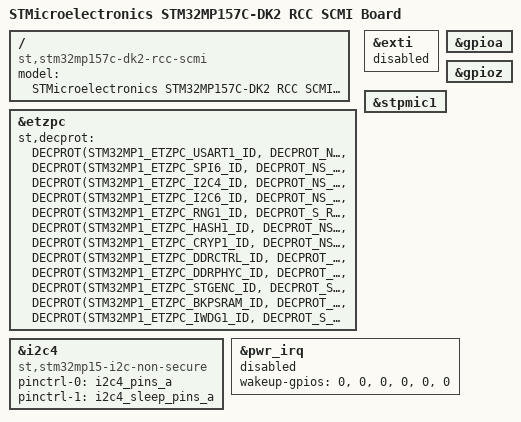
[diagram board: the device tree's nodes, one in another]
// SPDX-License-Identifier: (GPL-2.0+ OR BSD-3-Clause)
/*
 * Copyright (C) STMicroelectronics 2019-2026 - All Rights Reserved
 */

/dts-v1/;

#include "stm32mp157c-dk2.dts"

/ {
	model = "STMicroelectronics STM32MP157C-DK2 RCC SCMI Board";
	compatible = "st,stm32mp157c-dk2-rcc-scmi", "st,stm32mp157c-dk2", "st,stm32mp157";

	/delete-node/ scmi-regu;
};

&etzpc {
	st,decprot =
		<DECPROT(STM32MP1_ETZPC_USART1_ID, DECPROT_NS_RW, DECPROT_UNLOCK)>,
		<DECPROT(STM32MP1_ETZPC_SPI6_ID, DECPROT_NS_RW, DECPROT_UNLOCK)>,
		<DECPROT(STM32MP1_ETZPC_I2C4_ID, DECPROT_NS_RW, DECPROT_UNLOCK)>,
		<DECPROT(STM32MP1_ETZPC_I2C6_ID, DECPROT_NS_RW, DECPROT_UNLOCK)>,
		<DECPROT(STM32MP1_ETZPC_RNG1_ID, DECPROT_S_RW, DECPROT_UNLOCK)>,
		<DECPROT(STM32MP1_ETZPC_HASH1_ID, DECPROT_NS_RW, DECPROT_UNLOCK)>,
		<DECPROT(STM32MP1_ETZPC_CRYP1_ID, DECPROT_NS_RW, DECPROT_UNLOCK)>,
		<DECPROT(STM32MP1_ETZPC_DDRCTRL_ID, DECPROT_NS_R_S_W, DECPROT_LOCK)>,
		<DECPROT(STM32MP1_ETZPC_DDRPHYC_ID, DECPROT_NS_R_S_W, DECPROT_LOCK)>,
		<DECPROT(STM32MP1_ETZPC_STGENC_ID, DECPROT_S_RW, DECPROT_LOCK)>,
		<DECPROT(STM32MP1_ETZPC_BKPSRAM_ID, DECPROT_S_RW, DECPROT_LOCK)>,
		<DECPROT(STM32MP1_ETZPC_IWDG1_ID, DECPROT_S_RW, DECPROT_LOCK)>;
};

&exti {
	status = "disabled";
};

&gpioa {
	status = "okay";
};

&gpioz {
	/delete-property/ st,protreg;
};

&i2c4 {
	compatible = "st,stm32mp15-i2c-non-secure";
	pinctrl-0 = <&i2c4_pins_a>;
	pinctrl-1 = <&i2c4_sleep_pins_a>;
};

&stpmic1 {
	/delete-property/ interrupts-extended;
	/delete-property/ interrupt-controller;
	/delete-property/ #interrupt-cells;
	/delete-property/ wakeup-source;
	/delete-property/ st,pmic-it-id;
	/delete-property/ st,notif-it-id;
};

&pwr_irq {
	status = "disabled";
	wakeup-gpios = <0>, <0>, <0>, <0>, <0>, <0>;
};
